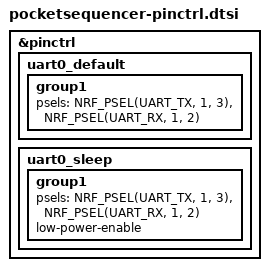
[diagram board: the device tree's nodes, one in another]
&pinctrl {
    uart0_default: uart0_default {
		group1 {
			psels = <NRF_PSEL(UART_TX, 1, 3)>,
				<NRF_PSEL(UART_RX, 1, 2)>;
		};
	};

	uart0_sleep: uart0_sleep {
		group1 {
			psels = <NRF_PSEL(UART_TX, 1, 3)>,
				<NRF_PSEL(UART_RX, 1, 2)>;
			low-power-enable;
		};
	};
};
